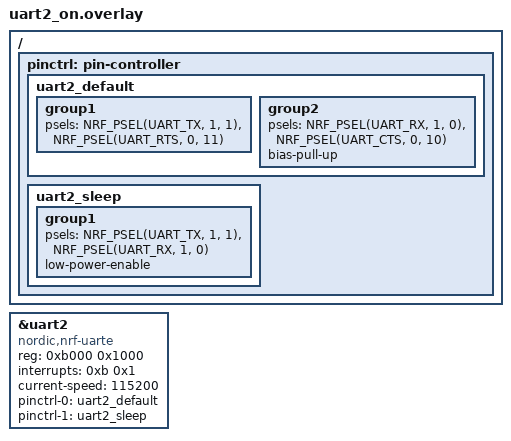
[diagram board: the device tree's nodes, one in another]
/ {
	pinctrl: pin-controller {
		uart2_default: uart2_default {
			group1 {
				psels = <NRF_PSEL(UART_TX, 1, 1)>,
						<NRF_PSEL(UART_RTS, 0, 11)>;
			};
			group2 {
				psels = <NRF_PSEL(UART_RX, 1, 0)>,
						<NRF_PSEL(UART_CTS, 0, 10)>;
				bias-pull-up;
			};
		};
		uart2_sleep: uart2_sleep {
			group1 {
				psels = <NRF_PSEL(UART_TX, 1, 1)>,
						<NRF_PSEL(UART_RX, 1, 0)>;
				low-power-enable;
			};
		};
	};
};

&uart2 {
	compatible = "nordic,nrf-uarte";
	reg = < 0xb000 0x1000 >;
	interrupts = < 0xb 0x1 >;
	status = "okay";
	current-speed = <115200>;
	pinctrl-0 = <&uart2_default>;
	pinctrl-1 = <&uart2_sleep>;
	pinctrl-names = "default", "sleep";
};


